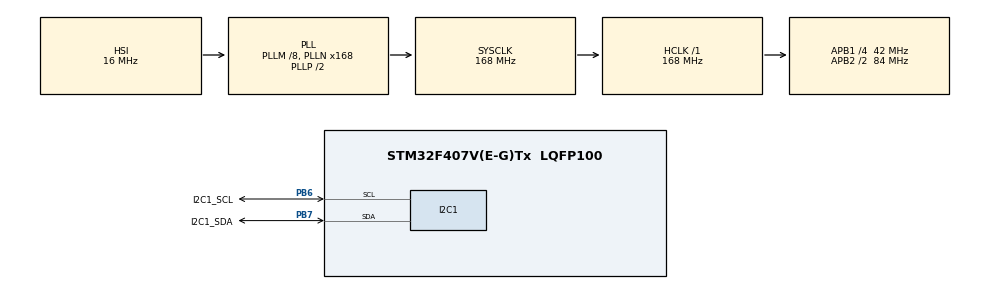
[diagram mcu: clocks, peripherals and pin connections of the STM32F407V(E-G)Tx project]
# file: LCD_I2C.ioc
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Mcu.Family=STM32F4
Mcu.Name=STM32F407V(E-G)Tx
Mcu.Package=LQFP100
NVIC.I2C1_ER_IRQn=true\:0\:0\:false\:false\:true\:true\:true\:true
NVIC.I2C1_EV_IRQn=true\:0\:0\:false\:false\:true\:true\:true\:true
NVIC.PriorityGroup=NVIC_PRIORITYGROUP_0
PA13.Mode=Serial_Wire
PA13.Signal=SYS_JTMS-SWDIO
PA14.Mode=Serial_Wire
PA14.Signal=SYS_JTCK-SWCLK
PB6.GPIO_Label=I2C1_SCL
PB6.Mode=I2C
PB6.Signal=I2C1_SCL
PB7.GPIO_Label=I2C1_SDA
PB7.Mode=I2C
PB7.Signal=I2C1_SDA
ProjectManager.HeapSize=0x200
ProjectManager.StackSize=0x400
ProjectManager.TargetToolchain=STM32CubeIDE
RCC.48MHZClocksFreq_Value=48000000
RCC.AHBFreq_Value=168000000
RCC.APB1CLKDivider=RCC_HCLK_DIV4
RCC.APB1Freq_Value=42000000
RCC.APB1TimFreq_Value=84000000
RCC.APB2CLKDivider=RCC_HCLK_DIV2
RCC.APB2Freq_Value=84000000
RCC.APB2TimFreq_Value=168000000
RCC.CortexFreq_Value=168000000
RCC.HCLKFreq_Value=168000000
RCC.HSE_VALUE=8000000
RCC.HSI_VALUE=16000000
RCC.LSE_VALUE=32768
RCC.PLLM=8
RCC.PLLN=168
RCC.PLLQ=7
RCC.SYSCLKFreq_VALUE=168000000
RCC.SYSCLKSource=RCC_SYSCLKSOURCE_PLLCLK
RCC.VCOOutputFreq_Value=336000000
board=STM32F407G-DISC1

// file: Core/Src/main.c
/* USER CODE BEGIN Header */
/**
  ******************************************************************************
  * @file           : main.c
  * @brief          : Main program body
  ******************************************************************************
  * @attention
  *
  * Copyright (c) 2024 STMicroelectronics.
  * All rights reserved.
  *
  * This software is licensed under terms that can be found in the LICENSE file
  * in the root directory of this software component.
  * If no LICENSE file comes with this software, it is provided AS-IS.
  *
  ******************************************************************************
  */
/* USER CODE END Header */
#include "main.h"

/* USER CODE BEGIN PD */
#define	CLEAR_SCREEN			0X01	//Clear Display Screen
#define DISPLAY_CURSOR_ON		0x0E 	//Display ON, Cursor ON
#define CURSON_ROW_1			0x80	//Force cursor to begin on 1st row
#define CURSOR_ROW_2			0xC0	//Change position to 1st coloumn of 2nd row
#define delay_t					1

//#define LCD_FUNCTION_SET1      0x33
//#define LCD_FUNCTION_SET2      0x32
//#define LCD_4BIT_2LINE_MODE    0x28
//#define LCD_DISP_CURS_ON       0x0E
//#define LCD_DISP_ON_CURS_OFF   0x0C  //Display on, cursor off
//#define LCD_DISPLAY_OFF        0x08
//#define LCD_DISPLAY_ON         0x04
//#define LCD_CLEAR_DISPLAY      0x01
//#define LCD_ENTRY_MODE_SET     0x04
//#define LCD_INCREMENT_CURSER   0x06
//#define LCD_SET_ROW1_COL1      0x80  //Force cursor to beginning ( 1st line)
//#define LCD_SET_ROW2_COL1      0xC0  //Force cursor to beginning ( 2nd line)
//#define LCD_MOVE_DISPLAY_LEFT  0x18
//#define LCD_MOVE_DISPLAY_RIGHT 0x1C
/* USER CODE END PD */

I2C_HandleTypeDef hi2c1;

/* USER CODE BEGIN PV */
const uint8_t slave_address = 0x3F;
/* USER CODE END PV */

void SystemClock_Config(void);
static void MX_GPIO_Init(void);
static void MX_I2C1_Init(void);
void lcd_init(void);
void i2c_transmit_command(uint8_t data);
void i2c_transmit_data(uint8_t data);
void t_i2c_transmit_command(uint8_t data);
void t_i2c_transmit_data(uint8_t data);

/* USER CODE BEGIN 0 */
void lcd_init(void) {
	//i2c_transmit_command(0x02); // Initialize LCD in 4-bit mode
	//i2c_transmit_command(0x28); // 2 line, 5x7 matrix in 4-bit mode
	i2c_transmit_command(CLEAR_SCREEN);
	HAL_Delay(delay_t); // Wait for clear to complete
	i2c_transmit_command(DISPLAY_CURSOR_ON);
	i2c_transmit_command(CURSON_ROW_1);

}

void i2c_transmit_command(uint8_t data)
{

	uint8_t command_en_on 	= ( (data & 0xF0) | 0x0C); //LED ON, RW = 0, RS = 0, EN =1;
	uint8_t command_en_off 	= ( command_en_on & (~(1 << 2)) );  //LED ON, RW = 0, RS = 0, EN =0;

	HAL_I2C_Master_Transmit(&hi2c1, slave_address << 1, &command_en_on, 1, HAL_MAX_DELAY);
	HAL_Delay(2);
	HAL_I2C_Master_Transmit(&hi2c1, slave_address << 1, &command_en_off, 1, HAL_MAX_DELAY);

	uint8_t command_lsb_en_on 	= (( (data << 4 ) & 0xF0 ) | 0X0C); //LED ON, RW = 0, RS = 0, EN =1;
	uint8_t command_lsb_en_off 	= ( command_lsb_en_on & (~(1 << 2)) );  //LED ON, RW = 0, RS = 0, EN =0;

	HAL_I2C_Master_Transmit(&hi2c1, slave_address << 1, &command_lsb_en_on, 1, HAL_MAX_DELAY);
	HAL_Delay(2);
	HAL_I2C_Master_Transmit(&hi2c1, slave_address << 1, &command_lsb_en_off, 1, HAL_MAX_DELAY);

}

void t_i2c_transmit_command(uint8_t data)
{
	uint8_t k = '\0', cmd = '\0',  cmd2 = '\0',  cmd3 = '\0';

	k = data & 0xF0;
	cmd = (k | 0x08) & (~0x01);
	cmd2 = (cmd | 0x04);
	cmd3 = (cmd & (~0x04));

	HAL_I2C_Master_Transmit(&hi2c1, slave_address << 1, &cmd2, 1, HAL_MAX_DELAY);
	HAL_Delay(2);
	HAL_I2C_Master_Transmit(&hi2c1, slave_address << 1, &cmd3, 1, HAL_MAX_DELAY);

	k = data << 4;
	cmd = (k | 0x08) & (~0x01);
	cmd2 = (cmd | 0x04);
	cmd3 = (cmd & (~0x04));

	HAL_I2C_Master_Transmit(&hi2c1, slave_address << 1, &cmd2, 1, HAL_MAX_DELAY);
	HAL_Delay(2);
	HAL_I2C_Master_Transmit(&hi2c1, slave_address << 1, &cmd3, 1, HAL_MAX_DELAY);

}

void t_i2c_transmit_data(uint8_t data)
{

	uint8_t k = '\0', cmd = '\0',  cmd2 = '\0',  cmd3 = '\0';

	k = data & 0xF0;
	cmd =  k | 0x08 | 0x01;
	cmd2 = (cmd | 0x04);
	cmd3 = (cmd & (~0x04));

	HAL_I2C_Master_Transmit(&hi2c1, slave_address << 1, &cmd2, 1, HAL_MAX_DELAY);
	HAL_Delay(2);
	HAL_I2C_Master_Transmit(&hi2c1, slave_address << 1, &cmd3, 1, HAL_MAX_DELAY);

	k = data << 4;
	cmd =  k | 0x08 | 0x01;
	cmd2 = (cmd | 0x04);
	cmd3 = (cmd & (~0x04));

	HAL_I2C_Master_Transmit(&hi2c1, slave_address << 1, &cmd2, 1, HAL_MAX_DELAY);
	HAL_Delay(2);
	HAL_I2C_Master_Transmit(&hi2c1, slave_address << 1, &cmd3, 1, HAL_MAX_DELAY);

}

void i2c_transmit_data(uint8_t data)
{

	uint8_t data_en_on 	= ( (data & 0xF0) | 0x0D); //LED ON, RW = 0, RS = 0, EN =1;
	uint8_t data_en_off 	= ( data_en_on & (~(1 << 2)) );  //LED ON, RW = 0, RS = 0, EN =0;

	HAL_I2C_Master_Transmit(&hi2c1, slave_address << 1, &data_en_on, 1, HAL_MAX_DELAY);
	HAL_Delay(2);
	HAL_I2C_Master_Transmit(&hi2c1, slave_address << 1, &data_en_off, 1, HAL_MAX_DELAY);

	uint8_t data_lsb_en_on 	= (( (data << 4 ) & 0xF0 ) | 0X0D); //LED ON, RW = 0, RS = 0, EN =1;
	uint8_t data_lsb_en_off 	= ( data_lsb_en_on & (~(1 << 2)) );  //LED ON, RW = 0, RS = 0, EN =0;

	HAL_I2C_Master_Transmit(&hi2c1, slave_address << 1, &data_lsb_en_on, 1, HAL_MAX_DELAY);
	HAL_Delay(2);
	HAL_I2C_Master_Transmit(&hi2c1, slave_address << 1, &data_lsb_en_off, 1, HAL_MAX_DELAY);

}

/* USER CODE END 0 */

int main(void)
{

  /* MCU Configuration--------------------------------------------------------*/

  /* Reset of all peripherals, Initializes the Flash interface and the Systick. */
  HAL_Init();

  /* Configure the system clock */
  SystemClock_Config();

  /* Initialize all configured peripherals */
  MX_GPIO_Init();
  MX_I2C1_Init();
  /* USER CODE BEGIN 2 */
  lcd_init();
  i2c_transmit_data('E');
  i2c_transmit_data('M');
  i2c_transmit_data('B');
  i2c_transmit_data('E');
  i2c_transmit_data('D');
  i2c_transmit_data('D');
  i2c_transmit_data('E');
  i2c_transmit_data('D');
  /* USER CODE END 2 */

  /* Infinite loop */
  while (1)
  {

  }
}

void SystemClock_Config(void)
{
  RCC_OscInitTypeDef RCC_OscInitStruct = {0};
  RCC_ClkInitTypeDef RCC_ClkInitStruct = {0};

  /** Configure the main internal regulator output voltage
  */
  __HAL_RCC_PWR_CLK_ENABLE();
  __HAL_PWR_VOLTAGESCALING_CONFIG(PWR_REGULATOR_VOLTAGE_SCALE1);

  /** Initializes the RCC Oscillators according to the specified parameters
  * in the RCC_OscInitTypeDef structure.
  */
  RCC_OscInitStruct.OscillatorType = RCC_OSCILLATORTYPE_HSI;
  RCC_OscInitStruct.HSIState = RCC_HSI_ON;
  RCC_OscInitStruct.HSICalibrationValue = RCC_HSICALIBRATION_DEFAULT;
  RCC_OscInitStruct.PLL.PLLState = RCC_PLL_ON;
  RCC_OscInitStruct.PLL.PLLSource = RCC_PLLSOURCE_HSI;
  RCC_OscInitStruct.PLL.PLLM = 8;
  RCC_OscInitStruct.PLL.PLLN = 168;
  RCC_OscInitStruct.PLL.PLLP = RCC_PLLP_DIV2;
  RCC_OscInitStruct.PLL.PLLQ = 7;
  if (HAL_RCC_OscConfig(&RCC_OscInitStruct) != HAL_OK)
  {
    Error_Handler();
  }

  /** Initializes the CPU, AHB and APB buses clocks
  */
  RCC_ClkInitStruct.ClockType = RCC_CLOCKTYPE_HCLK|RCC_CLOCKTYPE_SYSCLK
                              |RCC_CLOCKTYPE_PCLK1|RCC_CLOCKTYPE_PCLK2;
  RCC_ClkInitStruct.SYSCLKSource = RCC_SYSCLKSOURCE_PLLCLK;
  RCC_ClkInitStruct.AHBCLKDivider = RCC_SYSCLK_DIV1;
  RCC_ClkInitStruct.APB1CLKDivider = RCC_HCLK_DIV4;
  RCC_ClkInitStruct.APB2CLKDivider = RCC_HCLK_DIV2;

  if (HAL_RCC_ClockConfig(&RCC_ClkInitStruct, FLASH_LATENCY_5) != HAL_OK)
  {
    Error_Handler();
  }
}

static void MX_I2C1_Init(void)
{

  hi2c1.Instance = I2C1;
  hi2c1.Init.ClockSpeed = 100000;
  hi2c1.Init.DutyCycle = I2C_DUTYCYCLE_2;
  hi2c1.Init.OwnAddress1 = 0;
  hi2c1.Init.AddressingMode = I2C_ADDRESSINGMODE_7BIT;
  hi2c1.Init.DualAddressMode = I2C_DUALADDRESS_DISABLE;
  hi2c1.Init.OwnAddress2 = 0;
  hi2c1.Init.GeneralCallMode = I2C_GENERALCALL_DISABLE;
  hi2c1.Init.NoStretchMode = I2C_NOSTRETCH_DISABLE;
  if (HAL_I2C_Init(&hi2c1) != HAL_OK)
  {
    Error_Handler();
  }

}

static void MX_GPIO_Init(void)
{

  /* GPIO Ports Clock Enable */
  __HAL_RCC_GPIOA_CLK_ENABLE();
  __HAL_RCC_GPIOB_CLK_ENABLE();

}

void Error_Handler(void)
{
  __disable_irq();
  while (1)
  {
  }
}
